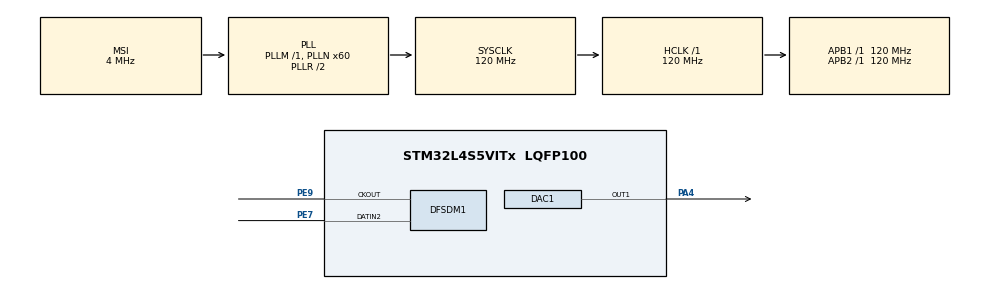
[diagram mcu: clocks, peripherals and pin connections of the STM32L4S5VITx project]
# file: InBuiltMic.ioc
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DAC1.DAC_Trigger-DAC_OUT1=DAC_TRIGGER_T2_TRGO
DFSDM1.Divider=15
DFSDM1.DmaMode_reg_FIL2=ENABLE
DFSDM1.FastMode_reg_FIL2=ENABLE
DFSDM1.FilterOrder_CH2=DFSDM_CHANNEL_SINC3_ORDER
DFSDM1.Filter_injChannel2_FIL0=__NULL
DFSDM1.Filter_regChannel_FIL0=__NULL
DFSDM1.Filter_regChannel_FIL2=DFSDM_CHANNEL_2
DFSDM1.Fosr_FIL2=1000
DFSDM1.SincOrder_FIL2=DFSDM_FILTER_SINC3_ORDER
Dma.DAC1_CH1.0.Direction=DMA_MEMORY_TO_PERIPH
Dma.DAC1_CH1.0.EventEnable=DISABLE
Dma.DAC1_CH1.0.Instance=DMA1_Channel3
Dma.DAC1_CH1.0.MemDataAlignment=DMA_MDATAALIGN_WORD
Dma.DAC1_CH1.0.MemInc=DMA_MINC_ENABLE
Dma.DAC1_CH1.0.Mode=DMA_CIRCULAR
Dma.DAC1_CH1.0.PeriphDataAlignment=DMA_PDATAALIGN_WORD
Dma.DAC1_CH1.0.PeriphInc=DMA_PINC_DISABLE
Dma.DAC1_CH1.0.Polarity=HAL_DMAMUX_REQUEST_GEN_RISING
Dma.DAC1_CH1.0.Priority=DMA_PRIORITY_LOW
Dma.DAC1_CH1.0.RequestNumber=1
Dma.DAC1_CH1.0.SignalID=NONE
Dma.DAC1_CH1.0.SyncEnable=DISABLE
Dma.DAC1_CH1.0.SyncPolarity=HAL_DMAMUX_SYNC_NO_EVENT
Dma.DAC1_CH1.0.SyncRequestNumber=1
Dma.DAC1_CH1.0.SyncSignalID=NONE
Dma.DFSDM1_FLT2.1.Direction=DMA_PERIPH_TO_MEMORY
Dma.DFSDM1_FLT2.1.EventEnable=DISABLE
Dma.DFSDM1_FLT2.1.Instance=DMA1_Channel1
Dma.DFSDM1_FLT2.1.MemDataAlignment=DMA_MDATAALIGN_WORD
Dma.DFSDM1_FLT2.1.MemInc=DMA_MINC_ENABLE
Dma.DFSDM1_FLT2.1.Mode=DMA_CIRCULAR
Dma.DFSDM1_FLT2.1.PeriphDataAlignment=DMA_PDATAALIGN_WORD
Dma.DFSDM1_FLT2.1.PeriphInc=DMA_PINC_DISABLE
Dma.DFSDM1_FLT2.1.Polarity=HAL_DMAMUX_REQUEST_GEN_RISING
Dma.DFSDM1_FLT2.1.Priority=DMA_PRIORITY_LOW
Dma.DFSDM1_FLT2.1.RequestNumber=1
Dma.DFSDM1_FLT2.1.SignalID=NONE
Dma.DFSDM1_FLT2.1.SyncEnable=DISABLE
Dma.DFSDM1_FLT2.1.SyncPolarity=HAL_DMAMUX_SYNC_NO_EVENT
Dma.DFSDM1_FLT2.1.SyncRequestNumber=1
Dma.DFSDM1_FLT2.1.SyncSignalID=NONE
Dma.Request0=DAC1_CH1
Dma.Request1=DFSDM1_FLT2
Mcu.Family=STM32L4
Mcu.Name=STM32L4S5VITx
Mcu.Package=LQFP100
NVIC.DFSDM1_FLT2_IRQn=true\:0\:0\:false\:true\:true\:1\:true\:true
NVIC.DMA1_Channel1_IRQn=true\:0\:0\:false\:true\:true\:2\:false\:true
NVIC.DMA1_Channel3_IRQn=true\:0\:0\:false\:true\:true\:3\:false\:true
NVIC.PriorityGroup=NVIC_PRIORITYGROUP_4
NVIC.TIM2_IRQn=true\:0\:0\:false\:true\:true\:4\:true\:true
PA13\ (JTMS/SWDIO).Signal=SYS_JTMS-SWDIO
PA4.Signal=COMP_DAC11_group
PB3\ (JTDO/TRACESWO).Signal=SYS_JTDO-SWO
PE7.Signal=S_DATAIN2DFSDM1
PE9.Signal=S_CKOUTDFSDM1
ProjectManager.HeapSize=0x200
ProjectManager.StackSize=0x400
ProjectManager.TargetToolchain=STM32CubeIDE
RCC.ADCFreq_Value=48000000
RCC.AHBFreq_Value=120000000
RCC.APB1Freq_Value=120000000
RCC.APB1TimFreq_Value=120000000
RCC.APB2Freq_Value=120000000
RCC.APB2TimFreq_Value=120000000
RCC.CortexFreq_Value=120000000
RCC.HCLKFreq_Value=120000000
RCC.HSE_VALUE=8000000
RCC.HSI48_VALUE=48000000
RCC.HSI_VALUE=16000000
RCC.LSE_VALUE=32768
RCC.MSI_VALUE=4000000
RCC.PLLN=60
RCC.PLLSAI1N=24
RCC.SYSCLKFreq_VALUE=120000000
RCC.SYSCLKSource=RCC_SYSCLKSOURCE_PLLCLK
RCC.USBFreq_Value=48000000
RCC.VCOOutputFreq_Value=240000000
SH.COMP_DAC11_group.0=DAC1_OUT1,DAC_OUT1
SH.S_CKOUTDFSDM1.0=DFSDM1_CKOUT,PDM_SPI_input_from_ch2_and_internal_clock
SH.S_CKOUTDFSDM1.1=DFSDM1_CKOUT,CKOUT
SH.S_DATAIN2DFSDM1.0=DFSDM1_DATIN2,PDM_SPI_input_from_ch2_and_internal_clock
TIM2.Period=15000
TIM2.TIM_MasterOutputTrigger=TIM_TRGO_UPDATE
VP_TIM2_VS_ClockSourceINT.Mode=Internal
board=B-L4S5I-IOT01A

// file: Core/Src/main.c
/* USER CODE BEGIN Header */
/**
 ******************************************************************************
 * @file           : main.c
 * @brief          : Main program body
 ******************************************************************************
 * @attention
 *
 * <h2><center>&copy; Copyright (c) 2021 STMicroelectronics.
 * All rights reserved.</center></h2>
 *
 * This software component is licensed by ST under BSD 3-Clause license,
 * the "License"; You may not use this file except in compliance with the
 * License. You may obtain a copy of the License at:
 *                        opensource.org/licenses/BSD-3-Clause
 *
 ******************************************************************************
 */
/* USER CODE END Header */
#include "main.h"

/* USER CODE BEGIN Includes */
#include "arm_math.h"
/* USER CODE END Includes */

/* USER CODE BEGIN PD */
#define ITM_Port32(n) (*((volatile unsigned long *) (0xE0000000+4*n)))
/* USER CODE END PD */

DAC_HandleTypeDef hdac1;
DMA_HandleTypeDef hdma_dac1_ch1;

DFSDM_Filter_HandleTypeDef hdfsdm1_filter2;
DFSDM_Channel_HandleTypeDef hdfsdm1_channel2;
DMA_HandleTypeDef hdma_dfsdm1_flt2;

TIM_HandleTypeDef htim2;

/* USER CODE BEGIN PV */
int32_t micData[8000];
uint32_t maskedData[8000];
uint32_t currentData;
int32_t currentDataIn;
uint16_t counter = 0;
/* USER CODE END PV */

void SystemClock_Config(void);
static void MX_GPIO_Init(void);
static void MX_DMA_Init(void);
static void MX_DFSDM1_Init(void);
static void MX_DAC1_Init(void);
static void MX_TIM2_Init(void);
static void MX_NVIC_Init(void);

int main(void) {

	/* MCU Configuration--------------------------------------------------------*/

	/* Reset of all peripherals, Initializes the Flash interface and the Systick. */
	HAL_Init();

	/* Configure the system clock */
	SystemClock_Config();

	/* Initialize all configured peripherals */
	MX_GPIO_Init();
	MX_DMA_Init();
	MX_DFSDM1_Init();
	MX_DAC1_Init();
	MX_TIM2_Init();

	/* Initialize interrupts */
	MX_NVIC_Init();
	/* USER CODE BEGIN 2 */

	//record 8000 samples at 8khz (1s of data)
	uint32_t micDataSize = 8000;

	//start DFSDM mic->digital with DMA, output is 32 bits signed int
	HAL_DFSDM_FilterRegularStart_DMA(&hdfsdm1_filter2, micData, micDataSize);
	HAL_Delay(500);

	//start DAC digital->speaker, input is 12 bits unsigned int so check conversion between micData and maskedData on callbacks
	HAL_DAC_Start_DMA(&hdac1, DAC_CHANNEL_1, maskedData, micDataSize,DAC_ALIGN_12B_R);

	//start timer on interrupt mode
	HAL_TIM_Base_Start_IT(&htim2);
	/* USER CODE END 2 */

	/* Infinite loop */
	while (1) {

	}
}

void SystemClock_Config(void) {
	RCC_OscInitTypeDef RCC_OscInitStruct = { 0 };
	RCC_ClkInitTypeDef RCC_ClkInitStruct = { 0 };
	RCC_PeriphCLKInitTypeDef PeriphClkInit = { 0 };

	/** Configure the main internal regulator output voltage
	 */
	if (HAL_PWREx_ControlVoltageScaling(PWR_REGULATOR_VOLTAGE_SCALE1_BOOST)
			!= HAL_OK) {
		Error_Handler();
	}
	/** Initializes the RCC Oscillators according to the specified parameters
	 * in the RCC_OscInitTypeDef structure.
	 */
	RCC_OscInitStruct.OscillatorType = RCC_OSCILLATORTYPE_MSI;
	RCC_OscInitStruct.MSIState = RCC_MSI_ON;
	RCC_OscInitStruct.MSICalibrationValue = 0;
	RCC_OscInitStruct.MSIClockRange = RCC_MSIRANGE_6;
	RCC_OscInitStruct.PLL.PLLState = RCC_PLL_ON;
	RCC_OscInitStruct.PLL.PLLSource = RCC_PLLSOURCE_MSI;
	RCC_OscInitStruct.PLL.PLLM = 1;
	RCC_OscInitStruct.PLL.PLLN = 60;
	RCC_OscInitStruct.PLL.PLLP = RCC_PLLP_DIV2;
	RCC_OscInitStruct.PLL.PLLQ = RCC_PLLQ_DIV2;
	RCC_OscInitStruct.PLL.PLLR = RCC_PLLR_DIV2;
	if (HAL_RCC_OscConfig(&RCC_OscInitStruct) != HAL_OK) {
		Error_Handler();
	}
	/** Initializes the CPU, AHB and APB buses clocks
	 */
	RCC_ClkInitStruct.ClockType = RCC_CLOCKTYPE_HCLK | RCC_CLOCKTYPE_SYSCLK
			| RCC_CLOCKTYPE_PCLK1 | RCC_CLOCKTYPE_PCLK2;
	RCC_ClkInitStruct.SYSCLKSource = RCC_SYSCLKSOURCE_PLLCLK;
	RCC_ClkInitStruct.AHBCLKDivider = RCC_SYSCLK_DIV1;
	RCC_ClkInitStruct.APB1CLKDivider = RCC_HCLK_DIV1;
	RCC_ClkInitStruct.APB2CLKDivider = RCC_HCLK_DIV1;

	if (HAL_RCC_ClockConfig(&RCC_ClkInitStruct, FLASH_LATENCY_5) != HAL_OK) {
		Error_Handler();
	}
	PeriphClkInit.PeriphClockSelection = RCC_PERIPHCLK_DFSDM1;
	PeriphClkInit.Dfsdm1ClockSelection = RCC_DFSDM1CLKSOURCE_PCLK;
	if (HAL_RCCEx_PeriphCLKConfig(&PeriphClkInit) != HAL_OK) {
		Error_Handler();
	}
}

/**
 * @brief NVIC Configuration.
 * @retval None
 */
static void MX_NVIC_Init(void) {
	/* DFSDM1_FLT2_IRQn interrupt configuration */
	HAL_NVIC_SetPriority(DFSDM1_FLT2_IRQn, 0, 0);
	HAL_NVIC_EnableIRQ(DFSDM1_FLT2_IRQn);
	/* DMA1_Channel1_IRQn interrupt configuration */
	HAL_NVIC_SetPriority(DMA1_Channel1_IRQn, 0, 0);
	HAL_NVIC_EnableIRQ(DMA1_Channel1_IRQn);
	/* DMA1_Channel3_IRQn interrupt configuration */
	HAL_NVIC_SetPriority(DMA1_Channel3_IRQn, 0, 0);
	HAL_NVIC_EnableIRQ(DMA1_Channel3_IRQn);
	/* TIM2_IRQn interrupt configuration */
	HAL_NVIC_SetPriority(TIM2_IRQn, 0, 0);
	HAL_NVIC_EnableIRQ(TIM2_IRQn);
}

static void MX_DAC1_Init(void) {

	DAC_ChannelConfTypeDef sConfig = { 0 };

	/** DAC Initialization
	 */
	hdac1.Instance = DAC1;
	if (HAL_DAC_Init(&hdac1) != HAL_OK) {
		Error_Handler();
	}
	/** DAC channel OUT1 config
	 */
	sConfig.DAC_SampleAndHold = DAC_SAMPLEANDHOLD_DISABLE;
	sConfig.DAC_Trigger = DAC_TRIGGER_T2_TRGO;
	sConfig.DAC_HighFrequency = DAC_HIGH_FREQUENCY_INTERFACE_MODE_DISABLE;
	sConfig.DAC_OutputBuffer = DAC_OUTPUTBUFFER_ENABLE;
	sConfig.DAC_ConnectOnChipPeripheral = DAC_CHIPCONNECT_DISABLE;
	sConfig.DAC_UserTrimming = DAC_TRIMMING_FACTORY;
	if (HAL_DAC_ConfigChannel(&hdac1, &sConfig, DAC_CHANNEL_1) != HAL_OK) {
		Error_Handler();
	}

}

static void MX_DFSDM1_Init(void) {

	hdfsdm1_filter2.Instance = DFSDM1_Filter2;
	hdfsdm1_filter2.Init.RegularParam.Trigger = DFSDM_FILTER_SW_TRIGGER;
	hdfsdm1_filter2.Init.RegularParam.FastMode = ENABLE;
	hdfsdm1_filter2.Init.RegularParam.DmaMode = ENABLE;
	hdfsdm1_filter2.Init.FilterParam.SincOrder = DFSDM_FILTER_SINC3_ORDER;
	hdfsdm1_filter2.Init.FilterParam.Oversampling = 1000;
	hdfsdm1_filter2.Init.FilterParam.IntOversampling = 1;
	if (HAL_DFSDM_FilterInit(&hdfsdm1_filter2) != HAL_OK) {
		Error_Handler();
	}
	hdfsdm1_channel2.Instance = DFSDM1_Channel2;
	hdfsdm1_channel2.Init.OutputClock.Activation = ENABLE;
	hdfsdm1_channel2.Init.OutputClock.Selection =
			DFSDM_CHANNEL_OUTPUT_CLOCK_SYSTEM;
	hdfsdm1_channel2.Init.OutputClock.Divider = 15;
	hdfsdm1_channel2.Init.Input.Multiplexer = DFSDM_CHANNEL_EXTERNAL_INPUTS;
	hdfsdm1_channel2.Init.Input.DataPacking = DFSDM_CHANNEL_STANDARD_MODE;
	hdfsdm1_channel2.Init.Input.Pins = DFSDM_CHANNEL_SAME_CHANNEL_PINS;
	hdfsdm1_channel2.Init.SerialInterface.Type = DFSDM_CHANNEL_SPI_RISING;
	hdfsdm1_channel2.Init.SerialInterface.SpiClock =
			DFSDM_CHANNEL_SPI_CLOCK_INTERNAL;
	hdfsdm1_channel2.Init.Awd.FilterOrder = DFSDM_CHANNEL_SINC3_ORDER;
	hdfsdm1_channel2.Init.Awd.Oversampling = 1;
	hdfsdm1_channel2.Init.Offset = 0;
	hdfsdm1_channel2.Init.RightBitShift = 0x00;
	if (HAL_DFSDM_ChannelInit(&hdfsdm1_channel2) != HAL_OK) {
		Error_Handler();
	}
	if (HAL_DFSDM_FilterConfigRegChannel(&hdfsdm1_filter2, DFSDM_CHANNEL_2,
			DFSDM_CONTINUOUS_CONV_ON) != HAL_OK) {
		Error_Handler();
	}

}

static void MX_TIM2_Init(void) {

	TIM_ClockConfigTypeDef sClockSourceConfig = { 0 };
	TIM_MasterConfigTypeDef sMasterConfig = { 0 };

	htim2.Instance = TIM2;
	htim2.Init.Prescaler = 0;
	htim2.Init.CounterMode = TIM_COUNTERMODE_UP;
	htim2.Init.Period = 15000;
	htim2.Init.ClockDivision = TIM_CLOCKDIVISION_DIV1;
	htim2.Init.AutoReloadPreload = TIM_AUTORELOAD_PRELOAD_DISABLE;
	if (HAL_TIM_Base_Init(&htim2) != HAL_OK) {
		Error_Handler();
	}
	sClockSourceConfig.ClockSource = TIM_CLOCKSOURCE_INTERNAL;
	if (HAL_TIM_ConfigClockSource(&htim2, &sClockSourceConfig) != HAL_OK) {
		Error_Handler();
	}
	sMasterConfig.MasterOutputTrigger = TIM_TRGO_UPDATE;
	sMasterConfig.MasterSlaveMode = TIM_MASTERSLAVEMODE_DISABLE;
	if (HAL_TIMEx_MasterConfigSynchronization(&htim2, &sMasterConfig)
			!= HAL_OK) {
		Error_Handler();
	}

}

static void MX_DMA_Init(void) {

	/* DMA controller clock enable */
	__HAL_RCC_DMAMUX1_CLK_ENABLE();
	__HAL_RCC_DMA1_CLK_ENABLE();

}

static void MX_GPIO_Init(void) {

	/* GPIO Ports Clock Enable */
	__HAL_RCC_GPIOA_CLK_ENABLE();
	__HAL_RCC_GPIOE_CLK_ENABLE();
	__HAL_RCC_GPIOB_CLK_ENABLE();

}

/* USER CODE BEGIN 4 */
void HAL_DFSDM_FilterRegConvCpltCallback(DFSDM_Filter_HandleTypeDef *hdfsdm_filter) {
	for (int i = 0; i < 4000; ++i) {
		//shift right to get only 12 bits (12 bits DAC resolution of speaker)
		maskedData[i] = (micData[i] >> 20);

		//make sign bit = 0 (equivalent to shifting up the graph)
		maskedData[i] = maskedData[i] & 0x7FF;
	}
}

void HAL_DFSDM_FilterRegConvHalfCpltCallback( DFSDM_Filter_HandleTypeDef *hdfsdm_filter) {
	for (int i = 4000; i < 8000; ++i) {
		//shift right to get only 12 bits (12 bits DAC resolution of speaker)
		maskedData[i] = (micData[i] >> 20);

		//make sign bit = 0 (equivalent to shifting up the graph)
		maskedData[i] = maskedData[i] & 0x7FF;
	}
}
void HAL_TIM_PeriodElapsedCallback(TIM_HandleTypeDef *htim) {
	//NOTE: enable line below for output digital data to speaker
	currentData = HAL_DAC_GetValue(&hdac1, DAC_CHANNEL_1);

	//NOTE: enable 3 lines below for getting mic data from DFSDM
	//currentDataIn = micData[counter];
	//++counter;
	//counter = counter%8000;

	//NOTE: enable line below for timing analysis on SWV trace log
	//ITM_Port32(31) = 44;
}

/* USER CODE END 4 */

void Error_Handler(void) {
	__disable_irq();
	while (1) {
	}
}

/************************ (C) COPYRIGHT STMicroelectronics *****END OF FILE****/
